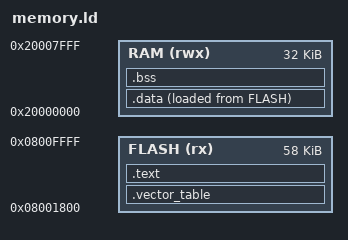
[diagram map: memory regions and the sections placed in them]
/* Linker script for ToSeven DM01 Cortex-M4F Firmware (loads at 0x08001800 above factory bootloader) */
MEMORY
{
  FLASH (rx) : ORIGIN = 0x08001800, LENGTH = 58K
  RAM (rwx)  : ORIGIN = 0x20000000, LENGTH = 32K
}

ENTRY(Reset_Handler)

SECTIONS
{
  .vector_table ORIGIN(FLASH) :
  {
    KEEP(*(.vector_table))
  } > FLASH

  .text : ALIGN(4)
  {
    *(.text .text.*)
    *(.rodata .rodata.*)
  } > FLASH

  .data : ALIGN(4)
  {
    _sdata = .;
    *(.data .data.*)
    . = ALIGN(4);
    _edata = .;
  } > RAM AT > FLASH

  _sidata = LOADADDR(.data);

  .bss (NOLOAD) : ALIGN(4)
  {
    _sbss = .;
    *(.bss .bss.* COMMON)
    . = ALIGN(4);
    _ebss = .;
  } > RAM

  /DISCARD/ :
  {
    *(.ARM.exidx .ARM.exidx.*)
  }
}

